# nrf54l05_application register map
Vendor: Nordic Semiconductor; Series: nrf54l; File version: 1
CPU: CM33 r0p4, little endian, MPU, FPU, 3 interrupt priority bits, 270 interrupts, 4 SAU regions
Registers are 32-bit, read-write, reset 0x0 unless marked. A register's access mark holds for its fields unless they carry their own. Offsets are from the block's base; [hi:lo] are bit positions; lines under a group give offsets from that group; {n}, {i} and the like mark numbered series; 'fields as' and 'values as' point back to an identical list.

## GLOBAL_CRACEN_S — CRACEN
Base 0x50048000
0x100 EVENTS_CRYPTOMASTER — Event indicating that interrupt triggered at Cryptomaster
  [0] EVENTS_CRYPTOMASTER
    0=NotGenerated (Event not generated); 1=Generated (Event generated)
0x104 EVENTS_RNG — Event indicating that interrupt triggered at RNG
  [0] EVENTS_RNG
    values as EVENTS_CRYPTOMASTER.EVENTS_CRYPTOMASTER
0x108 EVENTS_PKEIKG — Event indicating that interrupt triggered at PKE or IKG
  [0] EVENTS_PKEIKG
    values as EVENTS_CRYPTOMASTER.EVENTS_CRYPTOMASTER
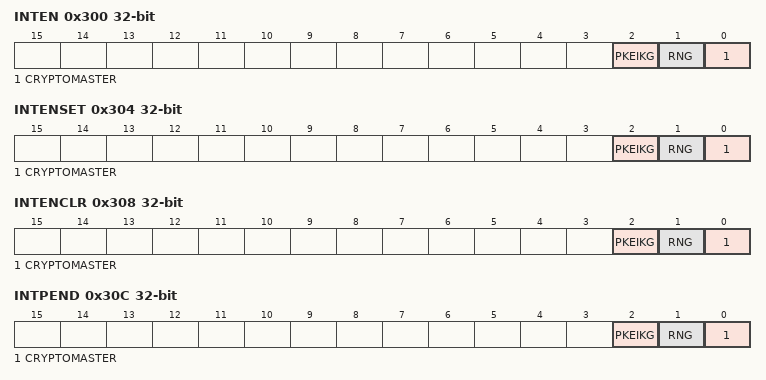
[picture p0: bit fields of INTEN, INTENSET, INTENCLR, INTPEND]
0x300 INTEN — Enable or disable interrupt
  [all] fields
    0=Disabled; 1=Enabled
  [2] PKEIKG — Enable or disable interrupt for event PKEIKG
  [1] RNG — Enable or disable interrupt for event RNG
  [0] CRYPTOMASTER — Enable or disable interrupt for event CRYPTOMASTER
0x304 INTENSET — Enable interrupt
  [all] fields
    on read: 0=Disabled (Read: Disabled); 1=Enabled (Read: Enabled) | on write: 1=Set (Enable)
  [2] PKEIKG — Write '1' to enable interrupt for event PKEIKG
  [1] RNG — Write '1' to enable interrupt for event RNG
  [0] CRYPTOMASTER — Write '1' to enable interrupt for event CRYPTOMASTER
0x308 INTENCLR — Disable interrupt
  [all] fields
    on read: 0=Disabled (Read: Disabled); 1=Enabled (Read: Enabled) | on write: 1=Clear (Disable)
  [2] PKEIKG — Write '1' to disable interrupt for event PKEIKG
  [1] RNG — Write '1' to disable interrupt for event RNG
  [0] CRYPTOMASTER — Write '1' to disable interrupt for event CRYPTOMASTER
0x30C INTPEND ro — Pending interrupts
  [all] fields
    on read: 0=NotPending (Read: Not pending); 1=Pending (Read: Pending)
  [2] PKEIKG — Read pending status of interrupt for event PKEIKG
  [1] RNG — Read pending status of interrupt for event RNG
  [0] CRYPTOMASTER — Read pending status of interrupt for event CRYPTOMASTER
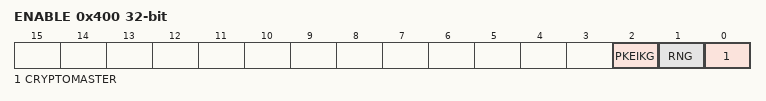
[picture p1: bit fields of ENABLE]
0x400 ENABLE — Enable CRACEN peripheral modules.
  [2] PKEIKG — Enable PKE and IKG
    0=Disabled (PKE and IKG disabled.); 1=Enabled (PKE and IKG enabled.)
  [1] RNG — Enable RNG
    0=Disabled (RNG disabled.); 1=Enabled (RNG enabled.)
  [0] CRYPTOMASTER — Enable cryptomaster
    0=Disabled (Cryptomaster disabled.); 1=Enabled (Cryptomaster enabled.)
0x404 SEEDVALID — Marks the SEED register as valid.
  [0] VALID — Marks the SEED as valid
    0=Disabled (Valid disabled.); 1=Enabled (Valid enabled.)
{0x410+4i} SEED[{i}] (i=0..11) wo — Description collection: Seed word [n] for symmetric and asymmetric key generation. This register is only writable from KMU.
  [31:0] VAL — Seed value
0x440 SEEDLOCK — Lock the access to the SEED register.
  [0] ENABLE — Enable the lock
    0=Disabled (Lock disabled.); 1=Enabled (Lock enabled.)
0x444 PROTECTEDRAMLOCK — Lock the access to the protected RAM.
  fields as SEEDLOCK

## GLOBAL_GLITCHDET_S — Voltage glitch detectors
Base 0x5004B000
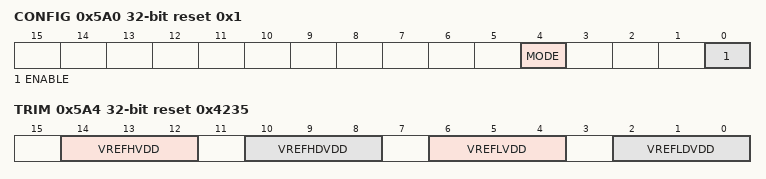
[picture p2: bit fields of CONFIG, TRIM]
0x5A0 CONFIG reset 0x1 — Configuration for glitch detector
  [4] MODE — Glitch detector mode
    0=High pass filter mode; 1=Cap divider mode
  [0] ENABLE — Enable glitch detector
    0=Disable glitch detector; 1=Enable glitch detector
0x5A4 TRIM reset 0x4235 — Trim configuration for glitch detector
  [14:12] VREFHVDD — Voltage trimming value for VREFH_VDD
    0=1V150 (0.150 V); 1=1V175 (0.175 V); 2=1V200 (1.200 V); 3=1V225 (1.225 V); 4=1V250 (1.250 V); 5=1V275 (1.275 V); 6=1V300 (1.300 V); 7=1V325 (1.325 V)
  [10:8] VREFHDVDD — Voltage trimming value for VREFH_DVDD
    0=0V950 (0.950 V); 1=0V975 (0.975 V); 2=1V000 (1.000 V); 3=1V025 (1.025 V); 4=1V050 (1.050 V); 5=1V075 (1.075 V); 6=1V100 (1.100 V); 7=1V125 (1.125 V)
  [6:4] VREFLVDD — Voltage trimming value for VREFL_VDD
    0=0V425 (0.425 V); 1=0V450 (0.450 V); 2=0V475 (0.475 V); 3=0V500 (0.500 V); 4=0V525 (0.525 V); 5=0V550 (0.550 V); 6=0V575 (0.575 V); 7=0V600 (0.600 V)
  [2:0] VREFLDVDD — Voltage trimming value for VREFL_DVDD
    0=0V675 (0.675 V); 1=0V700 (0.700 V); 2=0V725 (0.725 V); 3=0V750 (0.750 V); 4=0V775 (0.775 V); 5=0V800 (0.800 V); 6=0V825 (0.825 V); 7=0V850 (0.850 V)
0x5B0 DFT group — Unspecified
  0x00 ATB0CONFIG — Analog Test Bus 0 (ATB0) configuration
    [2:0] SELMUX — Select multiplexer for ATB0
      0=HiZ (High impedance); 1=VDDDIV (Measure/Force VDD_DIV voltage from external); 2=VDDDIG0V9 (Measure/Force VDD_DIG_0V9 voltage from external); 3=VSS; 4=GLITCHSRVDD3V0 (Internal signal - GLITCH_SR_VDD_3V0)
  0x04 ATB1CONFIG — Analog Test Bus 1 (ATB1) configuration
    [2:0] SELMUX — Select multiplexer for ATB1
      0=HiZ (High impedance); 1=VREFHVDD (Measure VREFH_VDD voltage); 2=VREFLVDD (Measure VREFL_VDD voltage); 3=VREFHDAVDD (Measure VREFH_DVDD voltage); 4=VREFLDVDD (Measure VREFL_DVDD voltage); 5=GLITCHSRDVDD3V0 (Internal signal - GLITCH_SR_DVDD_3V0)
  0x08 ATB2CONFIG — Analog Test Bus 2 (ATB2) configuration
    [1:0] SELMUX — Select multiplexer for ATB2
      0=HiZ (High impedance); 1=VTAMPORDVDD3V0 (Internal signal - VTAMP_OR_DVDD_3V0); 2=VTAMPORVDD3V0 (Internal signal - VTAMP_OR_VDD_3V0); 3=GLITCHNINT3V0 (Internal signal - GLITCH_N_INT_3V0)

## Notices in the file
Copyright (c) 2010 - 2025, Nordic Semiconductor ASA
All rights reserved.
Redistribution and use in source and binary forms, with or without modification,
are permitted provided that the following conditions are met:
1. Redistributions of source code must retain the above copyright notice, this
list of conditions and the following disclaimer.
2. Redistributions in binary form, except as embedded into a Nordic
Semiconductor ASA integrated circuit in a product or a software update for
such product, must reproduce the above copyright notice, this list of
conditions and the following disclaimer in the documentation and/or other
materials provided with the distribution.
3. Neither the name of Nordic Semiconductor ASA nor the names of its
contributors may be used to endorse or promote products derived from this
software without specific prior written permission.
4. This software, with or without modification, must only be used with a
Nordic Semiconductor ASA integrated circuit.
5. Any software provided in binary form under this license must not be reverse
engineered, decompiled, modified and/or disassembled.
THIS SOFTWARE IS PROVIDED BY NORDIC SEMICONDUCTOR ASA "AS IS" AND ANY EXPRESS
OR IMPLIED WARRANTIES, INCLUDING, BUT NOT LIMITED TO, THE IMPLIED WARRANTIES
OF MERCHANTABILITY, NONINFRINGEMENT, AND FITNESS FOR A PARTICULAR PURPOSE ARE
DISCLAIMED. IN NO EVENT SHALL NORDIC SEMICONDUCTOR ASA OR CONTRIBUTORS BE
LIABLE FOR ANY DIRECT, INDIRECT, INCIDENTAL, SPECIAL, EXEMPLARY, OR
CONSEQUENTIAL DAMAGES (INCLUDING, BUT NOT LIMITED TO, PROCUREMENT OF SUBSTITUTE
GOODS OR SERVICES; LOSS OF USE, DATA, OR PROFITS; OR BUSINESS INTERRUPTION)
HOWEVER CAUSED AND ON ANY THEORY OF LIABILITY, WHETHER IN CONTRACT, STRICT
LIABILITY, OR TORT (INCLUDING NEGLIGENCE OR OTHERWISE) ARISING IN ANY WAY OUT
OF THE USE OF THIS SOFTWARE, EVEN IF ADVISED OF THE POSSIBILITY OF SUCH DAMAGE.
